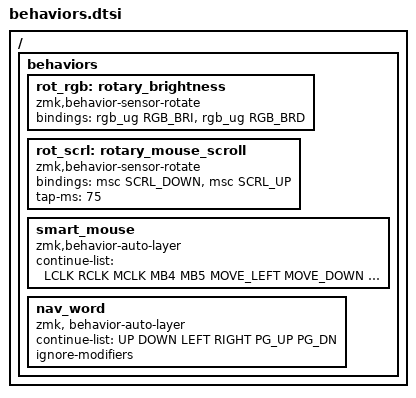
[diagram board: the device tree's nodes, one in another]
/ {
    behaviors {
        rot_rgb: rotary_brightness {
            compatible = "zmk,behavior-sensor-rotate";
            #sensor-binding-cells = <0>;
            bindings = <&rgb_ug RGB_BRI>, <&rgb_ug RGB_BRD>;
        };

        rot_scrl: rotary_mouse_scroll {
            compatible = "zmk,behavior-sensor-rotate";
            #sensor-binding-cells = <0>;
            bindings = <&msc SCRL_DOWN>, <&msc SCRL_UP>;
            tap-ms = <75>;
        };
        
        smart_mouse: smart_mouse {
            compatible = "zmk,behavior-auto-layer";
            #binding-cells = <1>;
            continue-list = <LCLK RCLK MCLK MB4 MB5 MOVE_LEFT MOVE_DOWN MOVE_UP MOVE_RIGHT SCRL_LEFT SCRL_DOWN SCRL_UP SCRL_RIGHT>;
        };

        nav_word: nav_word {
            compatible = "zmk, behavior-auto-layer";
            #binding-cells = <1>;
            continue-list = <UP DOWN LEFT RIGHT PG_UP PG_DN>;
            ignore-modifiers;
        };
    };
};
